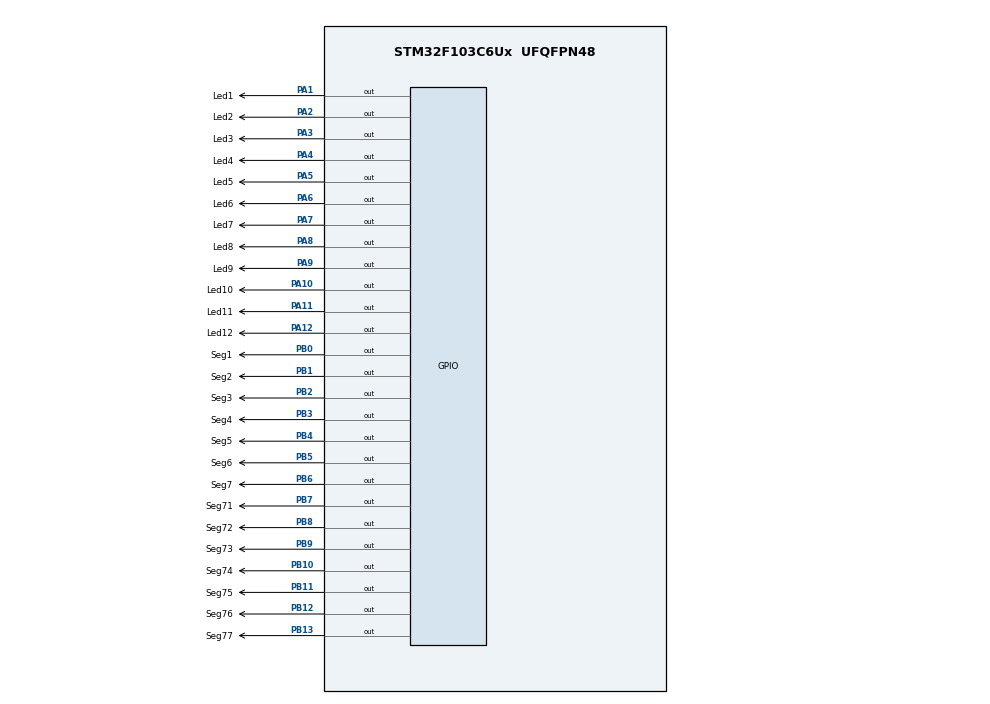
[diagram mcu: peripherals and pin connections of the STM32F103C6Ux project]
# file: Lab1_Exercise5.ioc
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Mcu.Family=STM32F1
Mcu.Name=STM32F103C6Ux
Mcu.Package=UFQFPN48
NVIC.PriorityGroup=NVIC_PRIORITYGROUP_4
PA1.GPIO_Label=Led1
PA1.Signal=GPIO_Output
PA10.GPIO_Label=Led10
PA10.Signal=GPIO_Output
PA11.GPIO_Label=Led11
PA11.Signal=GPIO_Output
PA12.GPIO_Label=Led12
PA12.Signal=GPIO_Output
PA2.GPIO_Label=Led2
PA2.Signal=GPIO_Output
PA3.GPIO_Label=Led3
PA3.Signal=GPIO_Output
PA4.GPIO_Label=Led4
PA4.Signal=GPIO_Output
PA5.GPIO_Label=Led5
PA5.Signal=GPIO_Output
PA6.GPIO_Label=Led6
PA6.Signal=GPIO_Output
PA7.GPIO_Label=Led7
PA7.Signal=GPIO_Output
PA8.GPIO_Label=Led8
PA8.Signal=GPIO_Output
PA9.GPIO_Label=Led9
PA9.Signal=GPIO_Output
PB0.GPIO_Label=Seg1
PB0.Signal=GPIO_Output
PB1.GPIO_Label=Seg2
PB1.Signal=GPIO_Output
PB10.GPIO_Label=Seg74
PB10.Signal=GPIO_Output
PB11.GPIO_Label=Seg75
PB11.Signal=GPIO_Output
PB12.GPIO_Label=Seg76
PB12.Signal=GPIO_Output
PB13.GPIO_Label=Seg77
PB13.Signal=GPIO_Output
PB2.GPIO_Label=Seg3
PB2.Signal=GPIO_Output
PB3.GPIO_Label=Seg4
PB3.Signal=GPIO_Output
PB4.GPIO_Label=Seg5
PB4.Signal=GPIO_Output
PB5.GPIO_Label=Seg6
PB5.Signal=GPIO_Output
PB6.GPIO_Label=Seg7
PB6.Signal=GPIO_Output
PB7.GPIO_Label=Seg71
PB7.Signal=GPIO_Output
PB8.GPIO_Label=Seg72
PB8.Signal=GPIO_Output
PB9.GPIO_Label=Seg73
PB9.Signal=GPIO_Output
ProjectManager.HeapSize=0x200
ProjectManager.StackSize=0x400
ProjectManager.TargetToolchain=STM32CubeIDE
RCC.APB1Freq_Value=8000000
RCC.APB2Freq_Value=8000000
VP_SYS_VS_ND.Mode=No_Debug
board=custom

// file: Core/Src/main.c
/* USER CODE BEGIN Header */
/**
  ******************************************************************************
  * @file           : main.c
  * @brief          : Main program body
  ******************************************************************************
  * @attention
  *
  * <h2><center>&copy; Copyright (c) 2024 STMicroelectronics.
  * All rights reserved.</center></h2>
  *
  * This software component is licensed by ST under BSD 3-Clause license,
  * the "License"; You may not use this file except in compliance with the
  * License. You may obtain a copy of the License at:
  *                        opensource.org/licenses/BSD-3-Clause
  *
  ******************************************************************************
  */
/* USER CODE END Header */
#include "main.h"
#include "lab1_exercise5.h"

void SystemClock_Config(void);
static void MX_GPIO_Init(void);

int main(void)
{
  /* USER CODE BEGIN 1 */
	int num_traffic =0; //Ex5
		int number_traffic = 0;
		int counter = 0; //Ex5
  /* USER CODE END 1 */

  /* MCU Configuration--------------------------------------------------------*/

  /* Reset of all peripherals, Initializes the Flash interface and the Systick. */
  HAL_Init();

  /* Configure the system clock */
  SystemClock_Config();

  /* Initialize all configured peripherals */
  MX_GPIO_Init();

  /* Infinite loop */
  while (1)
  {
	  Ex5(num_traffic++);
	  	  Ex51(number_traffic++);
	  	  Ex3(counter);
	  	  HAL_Delay(1000);
	  	  counter++;
	  	  if(num_traffic >= 10) num_traffic = 0;
	  	  if(number_traffic>=10) number_traffic = 0;
	  	  if(counter >= 10) counter = 0;
  }
}

void SystemClock_Config(void)
{
  RCC_OscInitTypeDef RCC_OscInitStruct = {0};
  RCC_ClkInitTypeDef RCC_ClkInitStruct = {0};

  /** Initializes the RCC Oscillators according to the specified parameters
  * in the RCC_OscInitTypeDef structure.
  */
  RCC_OscInitStruct.OscillatorType = RCC_OSCILLATORTYPE_HSI;
  RCC_OscInitStruct.HSIState = RCC_HSI_ON;
  RCC_OscInitStruct.HSICalibrationValue = RCC_HSICALIBRATION_DEFAULT;
  RCC_OscInitStruct.PLL.PLLState = RCC_PLL_NONE;
  if (HAL_RCC_OscConfig(&RCC_OscInitStruct) != HAL_OK)
  {
    Error_Handler();
  }
  /** Initializes the CPU, AHB and APB buses clocks
  */
  RCC_ClkInitStruct.ClockType = RCC_CLOCKTYPE_HCLK|RCC_CLOCKTYPE_SYSCLK
                              |RCC_CLOCKTYPE_PCLK1|RCC_CLOCKTYPE_PCLK2;
  RCC_ClkInitStruct.SYSCLKSource = RCC_SYSCLKSOURCE_HSI;
  RCC_ClkInitStruct.AHBCLKDivider = RCC_SYSCLK_DIV1;
  RCC_ClkInitStruct.APB1CLKDivider = RCC_HCLK_DIV1;
  RCC_ClkInitStruct.APB2CLKDivider = RCC_HCLK_DIV1;

  if (HAL_RCC_ClockConfig(&RCC_ClkInitStruct, FLASH_LATENCY_0) != HAL_OK)
  {
    Error_Handler();
  }
}

static void MX_GPIO_Init(void)
{
  GPIO_InitTypeDef GPIO_InitStruct = {0};

  /* GPIO Ports Clock Enable */
  __HAL_RCC_GPIOA_CLK_ENABLE();
  __HAL_RCC_GPIOB_CLK_ENABLE();

  /*Configure GPIO pin Output Level */
  HAL_GPIO_WritePin(GPIOA, Led1_Pin|Led2_Pin|Led3_Pin|Led4_Pin
                          |Led5_Pin|Led6_Pin|Led7_Pin|Led8_Pin
                          |Led9_Pin|Led10_Pin|Led11_Pin|Led12_Pin, GPIO_PIN_RESET);

  /*Configure GPIO pin Output Level */
  HAL_GPIO_WritePin(GPIOB, Seg1_Pin|Seg2_Pin|Seg3_Pin|Seg74_Pin
                          |Seg75_Pin|Seg76_Pin|Seg77_Pin|Seg4_Pin
                          |Seg5_Pin|Seg6_Pin|Seg7_Pin|Seg71_Pin
                          |Seg72_Pin|Seg73_Pin, GPIO_PIN_RESET);

  /*Configure GPIO pins : Led1_Pin Led2_Pin Led3_Pin Led4_Pin
                           Led5_Pin Led6_Pin Led7_Pin Led8_Pin
                           Led9_Pin Led10_Pin Led11_Pin Led12_Pin */
  GPIO_InitStruct.Pin = Led1_Pin|Led2_Pin|Led3_Pin|Led4_Pin
                          |Led5_Pin|Led6_Pin|Led7_Pin|Led8_Pin
                          |Led9_Pin|Led10_Pin|Led11_Pin|Led12_Pin;
  GPIO_InitStruct.Mode = GPIO_MODE_OUTPUT_PP;
  GPIO_InitStruct.Pull = GPIO_NOPULL;
  GPIO_InitStruct.Speed = GPIO_SPEED_FREQ_LOW;
  HAL_GPIO_Init(GPIOA, &GPIO_InitStruct);

  /*Configure GPIO pins : Seg1_Pin Seg2_Pin Seg3_Pin Seg74_Pin
                           Seg75_Pin Seg76_Pin Seg77_Pin Seg4_Pin
                           Seg5_Pin Seg6_Pin Seg7_Pin Seg71_Pin
                           Seg72_Pin Seg73_Pin */
  GPIO_InitStruct.Pin = Seg1_Pin|Seg2_Pin|Seg3_Pin|Seg74_Pin
                          |Seg75_Pin|Seg76_Pin|Seg77_Pin|Seg4_Pin
                          |Seg5_Pin|Seg6_Pin|Seg7_Pin|Seg71_Pin
                          |Seg72_Pin|Seg73_Pin;
  GPIO_InitStruct.Mode = GPIO_MODE_OUTPUT_PP;
  GPIO_InitStruct.Pull = GPIO_NOPULL;
  GPIO_InitStruct.Speed = GPIO_SPEED_FREQ_LOW;
  HAL_GPIO_Init(GPIOB, &GPIO_InitStruct);

}

void Error_Handler(void)
{
  __disable_irq();
  while (1)
  {
  }
}

/************************ (C) COPYRIGHT STMicroelectronics *****END OF FILE****/
